# R7FA4L1BD register map
Vendor: Renesas Electronics Corporation; Series: RA4; File version: 0.90.02
CPU: CM33 r0p4, little endian, MPU, FPU, VTOR, 4 interrupt priority bits, 96 interrupts
Registers are 32-bit, read-write, reset 0x0 unless marked. A register's access mark holds for its fields unless they carry their own. Offsets are from the block's base; [hi:lo] are bit positions; 'fields as' and 'values as' point back to an identical list.

## MSTP — Module Stop Control
Base 0x40084000
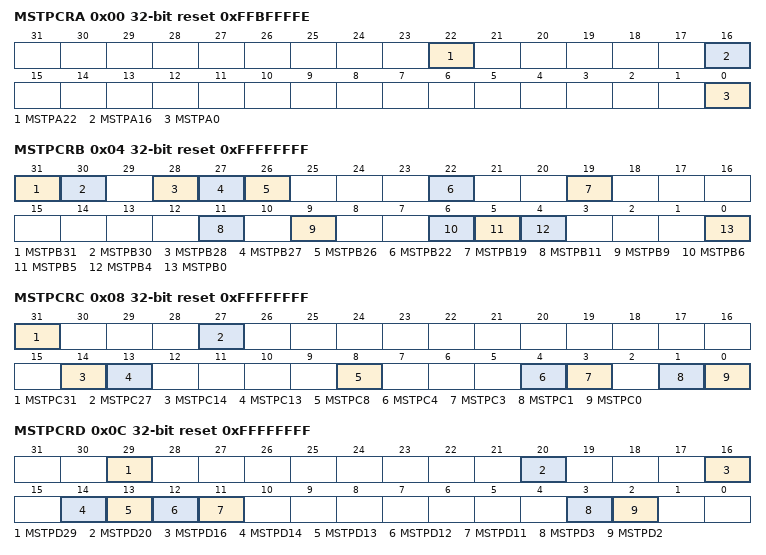
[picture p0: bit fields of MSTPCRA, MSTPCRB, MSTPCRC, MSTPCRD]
0x00 MSTPCRA reset 0xFFBFFFFE — Module Stop Control Register A
  [all] fields
    0=Cancel the module-stop state; 1=Enter the module-stop state
  [22] MSTPA22 — DMA Controller/Data Transfer Controller Module Stop
  [16] MSTPA16 — Sub Oscillation Stop Detection Module Stop
  [0] MSTPA0 — SRAM0 Module Stop
0x04 MSTPCRB reset 0xFFFFFFFF — Module Stop Control Register B
  [all] fields
    values as the fields of MSTPCRA
  [31] MSTPB31 — Serial Communication Interface 0 Module Stop
  [30] MSTPB30 — Serial Communication Interface 1 Module Stop
  [28] MSTPB28 — Serial Communication Interface 3 Module Stop
  [27] MSTPB27 — Serial Communication Interface 4 Module Stop
  [26] MSTPB26 — Serial Communication Interface 5 Module Stop
  [22] MSTPB22 — Serial Communication Interface 9 Module Stop
  [19] MSTPB19 — Serial Peripheral Interface 0 Module Stop
  [11] MSTPB11 — Universal Serial Bus 2.0 FS Interface Module Stop
  [9] MSTPB9 — I2C Bus Interface 0 Module Stop
  [6] MSTPB6 — Quad Serial Peripheral Interface Module Stop
  [5] MSTPB5 — IrDA Interface Module Stop
  [4] MSTPB4 — I3C Bus Interface Module Stop
  [0] MSTPB0 — Serial Interface UARTA Module Stop
0x08 MSTPCRC reset 0xFFFFFFFF — Module Stop Control Register C
  [all] fields
    values as the fields of MSTPCRA
  [31] MSTPC31 — RSIP-E11A Module Stop
  [27] MSTPC27 — Controller Area Network with Flexible Data-Rate Module Stop
  [14] MSTPC14 — Event Link Controller Module Stop
  [13] MSTPC13 — Data Operation Circuit Module Stop
  [8] MSTPC8 — Serial Sound Interface Enhanced Module Stop
  [4] MSTPC4 — Segment LCD Controller Module Stop
  [3] MSTPC3 — Capacitive Touch Sensing Unit Module Stop
  [1] MSTPC1 — Cyclic Redundancy Check Calculator Module Stop
  [0] MSTPC0 — Clock Frequency Accuracy Measurement Circuit Module Stop
0x0C MSTPCRD reset 0xFFFFFFFF — Module Stop Control Register D
  [all] fields
    values as the fields of MSTPCRA
  [29] MSTPD29 — Low-Power Analog Comparator Module Stop
  [20] MSTPD20 — 12-bit D/A Converter Module Stop
  [16] MSTPD16 — 12-bit A/D Converter 0 Module Stop
  [14] MSTPD14 — Port Output Enable for GPT Group A Module Stop
  [13] MSTPD13 — Port Output Enable for GPT Group B Module Stop
  [12] MSTPD12 — Port Output Enable for GPT Group C Module Stop
  [11] MSTPD11 — Port Output Enable for GPT Group D Module Stop
  [3] MSTPD3 — Low Power Asynchronous General Purpose Timer 0 Module Stop
  [2] MSTPD2 — Low Power Asynchronous General Purpose Timer 1 Module Stop
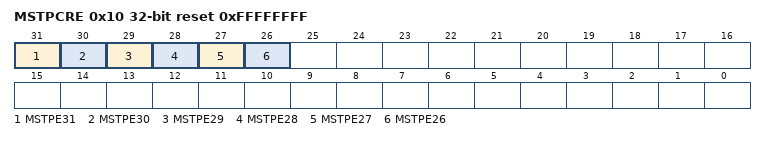
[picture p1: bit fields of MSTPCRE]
0x10 MSTPCRE reset 0xFFFFFFFF — Module Stop Control Register E
  [all] fields
    values as the fields of MSTPCRA
  [31] MSTPE31 — GPT0 Module Stop
  [30] MSTPE30 — GPT1 Module Stop
  [29] MSTPE29 — GPT2 Module Stop
  [28] MSTPE28 — GPT3 Module Stop
  [27] MSTPE27 — GPT4 Module Stop
  [26] MSTPE26 — GPT5 Module Stop

## POEG — Port Output Enable Module for GPT
Base 0x4008A000
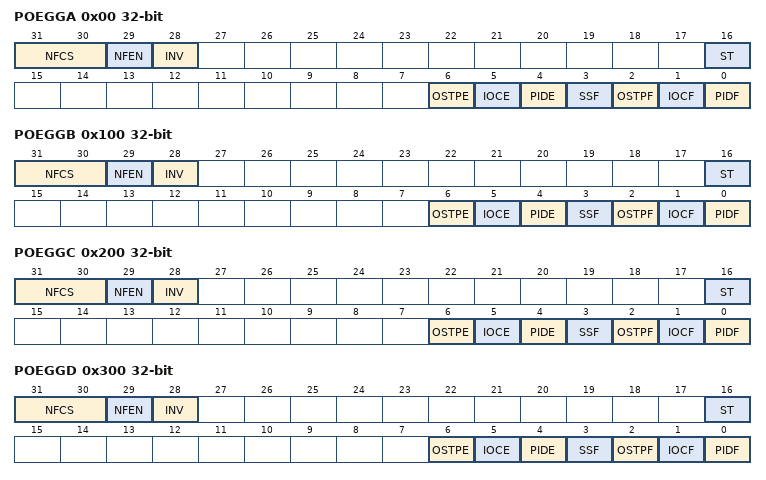
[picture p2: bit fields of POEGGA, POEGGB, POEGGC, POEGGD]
0x00 POEGGA — POEG Group A Setting Register
  [31:30] NFCS — Noise Filter Clock Select
    0=Sample GTETRGn pin input level three times every PCLKB; 1=Sample GTETRGn pin input level three times every PCLKB/8; 2=Sample GTETRGn pin input level three times every PCLKB/32; 3=Sample GTETRGn pin input level three times every PCLKB/128
  [29] NFEN — Noise Filter Enable
    0=Disable noise filtering; 1=Enable noise filtering
  [28] INV — GTETRGn Input Reverse
    0=Input GTETRGn as-is; 1=Input GTETRGn in reverse
  [16] ST ro — GTETRGn Input Status Flag
    0=GTETRGn input after filtering is 0; 1=GTETRGn input after filtering is 1
  [6] OSTPE — Oscillation Stop Detection Enable
    0=Disable output-disable requests from oscillation stop detection; 1=Enable output-disable requests from oscillation stop detection
  [5] IOCE — Enable for GPT Output-Disable Request
    0=Disable output-disable requests from GPT; 1=Enable output-disable requests from GPT
  [4] PIDE — Port Input Detection Enable
    0=Disable output-disable requests from the GTETRGn pins; 1=Enable output-disable requests from the GTETRGn pins
  [3] SSF — Software Stop Flag
    0=No output-disable request from software occurred; 1=Output-disable request from software occurred
  [2] OSTPF — Oscillation Stop Detection Flag
    0=No output-disable request from oscillation stop detection occurred; 1=Output-disable request from oscillation stop detection occurred
  [1] IOCF — Detection Flag for GPT Output-Disable Request
    0=No output-disable request from GPT occurred; 1=Output-disable request from GPT occurred
  [0] PIDF — Port Input Detection Flag
    0=No output-disable request from the GTETRGn pin occurred; 1=Output-disable request from the GTETRGn pin occurred
0x100 POEGGB — POEG Group B Setting Register
  fields as POEGGA
0x200 POEGGC — POEG Group C Setting Register
  fields as POEGGA
0x300 POEGGD — POEG Group D Setting Register
  fields as POEGGA
